AUTOSAR XML (schema 4.0)
package /ADAS_Components
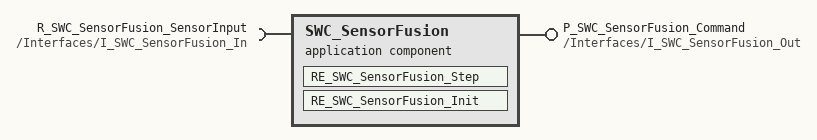
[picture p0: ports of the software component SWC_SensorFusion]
  application sw component type SWC_SensorFusion  # AUTOSAR Application SWC SWC_SensorFusion for ADAS control sub-system
    provide port P_SWC_SensorFusion_Command: provided-interface=/Interfaces/I_SWC_SensorFusion_Out
    require port R_SWC_SensorFusion_SensorInput: required-interface=/Interfaces/I_SWC_SensorFusion_In
    behavior SWC_SensorFusion_Behavior
      runnable RE_SWC_SensorFusion_Step: symbol=SWC_SensorFusion_Step
      runnable RE_SWC_SensorFusion_Init: symbol=SWC_SensorFusion_Init
  sender receiver interface I_SWC_SensorFusion_Out  # Sender Receiver Interface for SWC_SensorFusion outputs
    data DE_SWC_SensorFusion_Signal: type=/AUTOSAR/Platform/uint32
  sender receiver interface I_SWC_SensorFusion_In  # Sender Receiver Interface for SWC_SensorFusion inputs
    data DE_SWC_SensorFusion_RawData: type=/AUTOSAR/Platform/uint16
